# MCASP3_CFG register map
Vendor: Texas Instruments
Peripheral module from a debugger description file (folder J7_AHP).
Registers are 32-bit, read-write, reset 0x0 unless marked. A register's access mark holds for its fields unless they carry their own. Offsets are as the file gives them; lines under a group give offsets from that group; [hi:lo] are bit positions; {n}, {i} and the like mark numbered series; 'fields as' and 'values as' point back to an identical list; <NAME> marks a mode.

## MCASP3_CFG
0x00 CFG_PID ro reset 0x44307B02
  [31:0] REV — Identifies revision of peripheral.
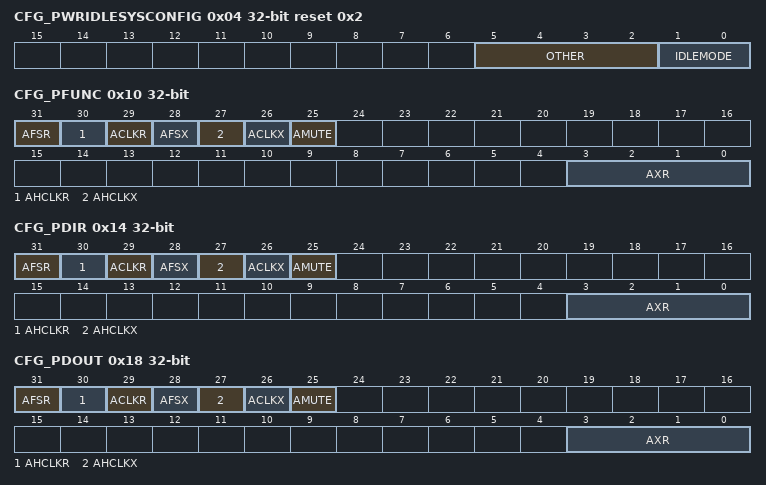
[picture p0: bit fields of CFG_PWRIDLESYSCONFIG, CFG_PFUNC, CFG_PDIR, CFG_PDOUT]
0x04 CFG_PWRIDLESYSCONFIG access per field reset 0x2
  [5:2] OTHER rw — Reserved for future programming.
  [1:0] IDLEMODE rw — Power management Configuration of the local target state management mode. By definition, target can handle read/write transaction as long as it is out of IDLE state.
0x10 CFG_PFUNC access per field
  [31] AFSR rw — Determines if AFSR pin functions as McASP or GPIO.
  [30] AHCLKR rw — Determines if AHCLKR pin functions as McASP or GPIO.
  [29] ACLKR rw — Determines if ACLKR pin functions as McASP or GPIO.
  [28] AFSX rw — Determines if AFSX pin functions as McASP or GPIO.
  [27] AHCLKX rw — Determines if AHCLKX pin functions as McASP or GPIO.
  [26] ACLKX rw — Determines if ACLKX pin functions as McASP or GPIO.
  [25] AMUTE rw — Determines if AMUTE pin functions as McASP or GPIO.
  [3:0] AXR rw — Determines if AXRn pin functions as McASP or GPIO.
0x14 CFG_PDIR access per field
  [31] AFSR rw — Determines if AFSR pin functions as an input or output.
  [30] AHCLKR rw — Determines if AHCLKR pin functions as an input or output.
  [29] ACLKR rw — Determines if ACLKR pin functions as an input or output.
  [28] AFSX rw — Determines if AFSX pin functions as an input or output.
  [27] AHCLKX rw — Determines if AHCLKX pin functions as an input or output.
  [26] ACLKX rw — Determines if ACLKX pin functions as an input or output.
  [25] AMUTE rw — Determines if AMUTE pin functions as an input or output.
  [3:0] AXR rw — Determines if AXRn pin functions as an input or output.
0x18 CFG_PDOUT access per field
  [31] AFSR rw — Determines drive on AFSR output pin when the corresponding PFUNC[31] and PDIR[31] bits are set to 1.
  [30] AHCLKR rw — Determines drive on AHCLKR output pin when the corresponding PFUNC[30] and PDIR[30] bits are set to 1.
  [29] ACLKR rw — Determines drive on ACLKR output pin when the corresponding PFUNC[29] and PDIR[29] bits are set to 1.
  [28] AFSX rw — Determines drive on AFSX output pin when the corresponding PFUNC[28] and PDIR[28] bits are set to 1.
  [27] AHCLKX rw — Determines drive on AHCLKX output pin when the corresponding PFUNC[27] and PDIR[27] bits are set to 1.
  [26] ACLKX rw — Determines drive on ACLKX output pin when the corresponding PFUNC[26] and PDIR[26] bits are set to 1.
  [25] AMUTE rw — Determines drive on AMUTE output pin when the corresponding PFUNC[25] and PDIR[25] bits are set to 1.
  [3:0] AXR rw — Determines drive on AXR[n] output pin when the corresponding PFUNC[n] and PDIR[n] bits are set to 1.
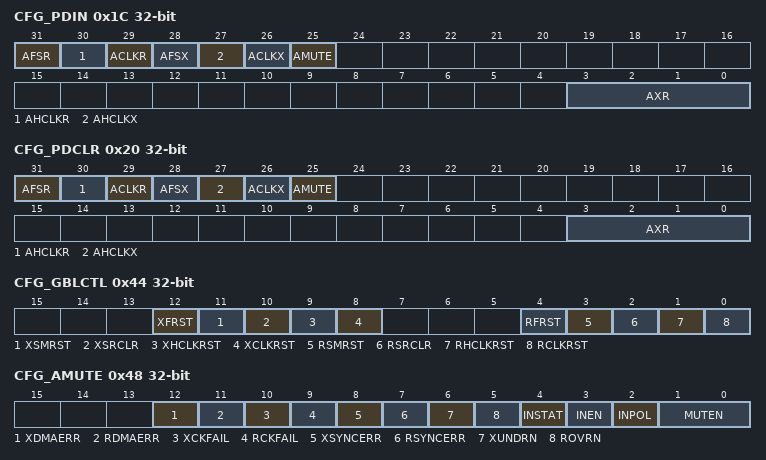
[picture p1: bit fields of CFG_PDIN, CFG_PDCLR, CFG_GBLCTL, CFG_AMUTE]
0x1C CFG_PDIN access per field
  [31] AFSR rw — Logic level on AFSR pin.
  [30] AHCLKR rw — Logic level on AHCLKR pin.
  [29] ACLKR rw — Logic level on ACLKR pin.
  [28] AFSX rw — Logic level on AFSX pin.
  [27] AHCLKX rw — Logic level on AHCLKX pin.
  [26] ACLKX rw — Logic level on ACLKX pin.
  [25] AMUTE rw — Logic level on AMUTE pin.
  [3:0] AXR rw — Logic level on AXR[n] pin.
0x20 CFG_PDCLR access per field
  [31] AFSR rw — Allows the corresponding AFSR bit in PDOUT to be cleared to a logic low without affecting other I/O pins controlled by the same port.
  [30] AHCLKR rw — Allows the corresponding AHCLKR bit in PDOUT to be cleared to a logic low without affecting other I/O pins controlled by the same port.
  [29] ACLKR rw — Allows the corresponding ACLKR bit in PDOUT to be cleared to a logic low without affecting other I/O pins controlled by the same port.
  [28] AFSX rw — Allows the corresponding AFSX bit in PDOUT to be cleared to a logic low without affecting other I/O pins controlled by the same port.
  [27] AHCLKX rw — Allows the corresponding AHCLKX bit in PDOUT to be cleared to a logic low without affecting other I/O pins controlled by the same port.
  [26] ACLKX rw — Allows the corresponding ACLKX bit in PDOUT to be cleared to a logic low without affecting other I/O pins controlled by the same port.
  [25] AMUTE rw — Allows the corresponding AMUTE bit in PDOUT to be cleared to a logic low without affecting other I/O pins controlled by the same port.
  [3:0] AXR rw — Allows the corresponding AXR[n] bit in PDOUT to be cleared to a logic low without affecting other I/O pins controlled by the same port.
0x44 CFG_GBLCTL access per field
  [12] XFRST rw — Transmit frame sync generator reset enable bit.
  [11] XSMRST rw — Transmit state machine reset enable bit.
  [10] XSRCLR rw — Transmit serializer clear enable bit. By clearing then setting this bit, the transmit buffer is flushed to an empty state [XDATA = 1]. If XSMRST = 1, XSRCLR = 1, XDATA = 1, and XBUF is not loaded with new data before the start of the next active time slot, an underrun will occur.
  [9] XHCLKRST rw — Transmit high-frequency clock divider reset enable bit.
  [8] XCLKRST rw — Transmit clock divider reset enable bit.
  [4] RFRST rw — Receive frame sync generator reset enable bit.
  [3] RSMRST rw — Receive state machine reset enable bit.
  [2] RSRCLR rw — Receive serializer clear enable bit. By clearing then setting this bit, the receive buffer is flushed.
  [1] RHCLKRST rw — Receive high-frequency clock divider reset enable bit.
  [0] RCLKRST rw — Receive high-frequency clock divider reset enable bit.
0x48 CFG_AMUTE access per field
  [12] XDMAERR rw — If transmit DMA error [XDMAERR], drive AMUTE active enable bit.
  [11] RDMAERR rw — If receive DMA error [RDMAERR], drive AMUTE active enable bit.
  [10] XCKFAIL rw — If transmit clock failure [XCKFAIL], drive AMUTE active enable bit.
  [9] RCKFAIL rw — If receive clock failure [RCKFAIL], drive AMUTE active enable bit.
  [8] XSYNCERR rw — If unexpected transmit frame sync error [XSYNCERR], drive AMUTE active enable bit.
  [7] RSYNCERR rw — If unexpected receive frame sync error [RSYNCERR], drive AMUTE active enable bit.
  [6] XUNDRN rw — If transmit underrun error [XUNDRN], drive AMUTE active enable bit.
  [5] ROVRN rw — If receiver overrun error [ROVRN], drive AMUTE active enable bit.
  [4] INSTAT ro — Determines drive on AXRn pin when PFUNC[n] and PDIR[n] bits are set to 1.
  [3] INEN rw — Drive AMUTE active when AMUTEIN error is active [INSTAT = 1].
  [2] INPOL rw — Audio mute in [AMUTEIN] polarity select bit.
  [1:0] MUTEN rw — AMUTE pin enable bit [unless overridden by GPIO registers].
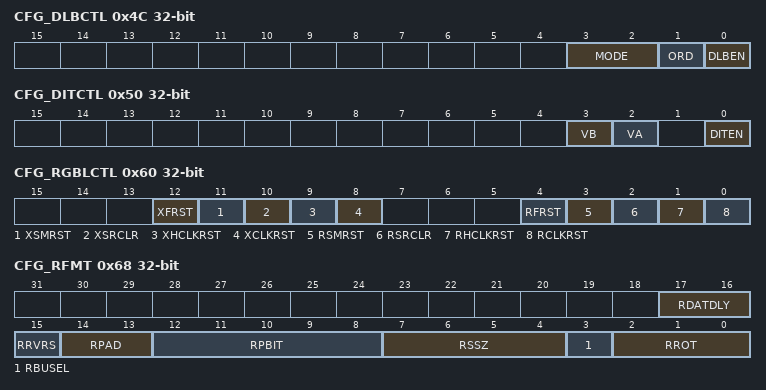
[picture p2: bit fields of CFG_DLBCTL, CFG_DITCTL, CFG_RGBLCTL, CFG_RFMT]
0x4C CFG_DLBCTL access per field
  [3:2] MODE rw — Loopback generator mode bits. Applies only when loopback mode is enabled [DLBEN = 1].
  [1] ORD rw — Loopback order bit when loopback mode is enabled [DLBEN = 1].
  [0] DLBEN rw — Loopback mode enable bit.
0x50 CFG_DITCTL access per field
  [3] VB rw — Valid bit for odd time slots [DIT right subframe].
  [2] VA rw — Valid bit for even time slots [DIT left subframe].
  [0] DITEN rw — DIT mode enable bit. DITEN should only be changed while the XSMRST bit in GBLCTL is in reset [and for startup, XSRCLR also in reset]. However, it is not necessary to reset the XCLKRST or XHCLKRST bits in GBLCTL to change DITEN.
0x60 CFG_RGBLCTL access per field
  [12] XFRST ro — Transmit frame sync generator reset enable bit. A read of this bit returns the XFRST bit value of GBLCTL. Writes have no effect.
  [11] XSMRST ro — Transmit state machine reset enable bit. A read of this bit returns the XSMRST bit value of GBLCTL. Writes have no effect.
  [10] XSRCLR ro — Transmit serializer clear enable bit. A read of this bit returns the XSRCLR bit value of GBLCTL. Writes have no effect.
  [9] XHCLKRST ro — Transmit high-frequency clock divider reset enable bit. A read of this bit returns the XHCLKRST bit value of GBLCTL. Writes have no effect.
  [8] XCLKRST ro — Transmit clock divider reset enable bit. A read of this bit returns the XCLKRST bit value of GBLCTL. Writes have no effect.
  [4] RFRST rw — Receive frame sync generator reset enable bit. A write to this bit affects the RFRST bit of GBLCTL.
  [3] RSMRST rw — Receive state machine reset enable bit. A write to this bit affects the RSMRST bit of GBLCTL.
  [2] RSRCLR rw — Receive serializer clear enable bit. A write to this bit affects the RSRCLR bit of GBLCTL.
  [1] RHCLKRST rw — Receive high-frequency clock divider reset enable bit. A write to this bit affects the RHCLKRST bit of GBLCTL.
  [0] RCLKRST rw — Receive clock divider reset enable bit. A write to this bit affects the RCLKRST bit of GBLCTL.
0x64 CFG_RMASK
  [31:0] RMASK — Receive data mask n enable bit.
0x68 CFG_RFMT access per field
  [17:16] RDATDLY rw — Receive bit delay.
  [15] RRVRS rw — Receive serial bitstream order.
  [14:13] RPAD rw — Pad value for extra bits in slot not belonging to the word. This field only applies to bits when RMASK[n] = 0.
  [12:8] RPBIT rw — RPBIT value determines which bit [as read by the CPU or DMA from RBUF[n]] is used to pad the extra bits. This field only applies when RPAD = 2h.
  [7:4] RSSZ rw — Receive slot size.
  [3] RBUSEL rw — Selects whether reads from serializer buffer XRBUF[n] originate from the configuration bus [CFG] or the data [DAT] port.
  [2:0] RROT rw — Right-rotation value for receive rotate right format unit.
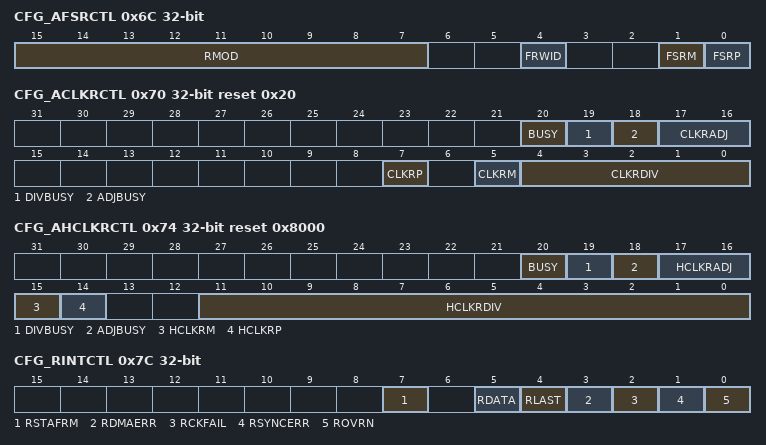
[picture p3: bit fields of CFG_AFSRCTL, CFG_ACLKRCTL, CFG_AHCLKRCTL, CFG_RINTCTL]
0x6C CFG_AFSRCTL access per field
  [15:7] RMOD rw — Receive frame sync mode select bits. 1FFh = Reserved from 181h to 1FFh.
  [4] FRWID rw — Receive frame sync width select bit indicates the width of the receive frame sync [AFSR] during its active period.
  [1] FSRM rw — Receive frame sync generation select bit.
  [0] FSRP rw — Receive frame sync polarity select bit.
0x70 CFG_ACLKRCTL access per field reset 0x20
  [20] BUSY rw — Status: logical OR of DIVBUSY, ADJBUSY
  [19] DIVBUSY rw — Status: divide ratio change in progress
  [18] ADJBUSY rw — Status: one-shot adjustment in progress
  [17:16] CLKRADJ wo — CLKRDIV one-shot adjustment
  [7] CLKRP rw — Receive bitstream clock polarity select bit.
  [5] CLKRM rw — Receive bit clock source bit. Note that this bit does not have any effect, if ACLKXCTL.ASYNC = 0.
  [4:0] CLKRDIV rw — Receive bit clock divide ratio bits determine the divide-down ratio from AHCLKR to ACLKR. Note that this bit does not have any effect, if ACLKXCTL.ASYNC = 0.
0x74 CFG_AHCLKRCTL access per field reset 0x8000
  [20] BUSY rw — Status: logical OR of DIVBUSY, ADJBUSY
  [19] DIVBUSY rw — Status: divide ratio change in progress?
  [18] ADJBUSY rw — Status: one-shot adjustment in progress?
  [17:16] HCLKRADJ wo — HCLKRDIV one-shot adjustment
  [15] HCLKRM rw — Receive high-frequency clock source bit.
  [14] HCLKRP rw — Receive bitstream high-frequency clock polarity select bit.
  [11:0] HCLKRDIV rw — Receive high-frequency clock divide ratio bits determine the divide-down ratio from AUXCLK to AHCLKR.
0x78 CFG_RTDM
  [31:0] RTDMS — Receiver mode during TDM time slot n.
0x7C CFG_RINTCTL access per field
  [7] RSTAFRM rw — Receive start of frame interrupt enable bit.
  [5] RDATA rw — Receive data ready interrupt enable bit.
  [4] RLAST rw — Receive last slot interrupt enable bit.
  [3] RDMAERR rw — Receive DMA error interrupt enable bit.
  [2] RCKFAIL rw — Receive clock failure interrupt enable bit.
  [1] RSYNCERR rw — Unexpected receive frame sync interrupt enable bit.
  [0] ROVRN rw — Receiver overrun interrupt enable bit.
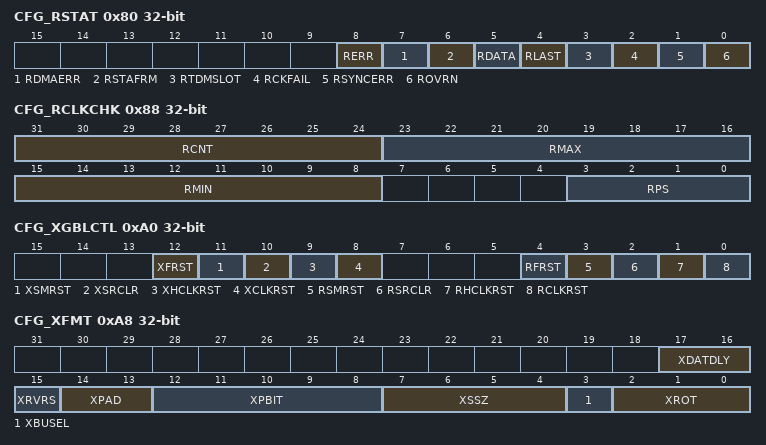
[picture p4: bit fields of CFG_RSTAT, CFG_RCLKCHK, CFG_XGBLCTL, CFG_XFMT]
0x80 CFG_RSTAT access not given
  [8] RERR rw — RERR bit always returns a logic-OR of: ROVRN OR RSYNCERR OR RCKFAIL OR RDMAERR. Allows a single bit to be checked to determine if a receiver error interrupt has occurred.
  [7] RDMAERR — Receive DMA error flag. RDMAERR is set when the CPU or DMA reads more serializers through the data port in a given time slot than were programmed as receivers. Causes a receive interrupt [RINT], if this bit is set and RDMAERR in RINTCTL is set. This bit is cleared by writing a 1 to this bit. Writing a 0 to this bit has no effect. (access R/W1TC)
  [6] RSTAFRM — Receive start of frame flag. Causes a receive interrupt [RINT], if this bit is set and RSTAFRM in RINTCTL is set. This bit is cleared by writing a 1 to this bit. Writing a 0 to this bit has no effect. (access R/W1TC)
  [5] RDATA — Receive data ready flag. Causes a receive interrupt [RINT], if this bit is set and RDATA in RINTCTL is set. This bit is cleared by writing a 1 to this bit. Writing a 0 to this bit has no effect. (access R/W1TC)
  [4] RLAST — Receive last slot flag. RLAST is set along with RDATA, if the current slot is the last slot in a frame. Causes a receive interrupt [RINT], if this bit is set and RLAST in RINTCTL is set. This bit is cleared by writing a 1 to this bit. Writing a 0 to this bit has no effect. (access R/W1TC)
  [3] RTDMSLOT ro — Returns the LSB of RSLOT. Allows a single read of RSTAT to determine whether the current TDM time slot is even or odd.
  [2] RCKFAIL — Receive clock failure flag. RCKFAIL is set when the receive clock failure detection circuit reports an error. Causes a receive interrupt [RINT], if this bit is set and RCKFAIL in RINTCTL is set. This bit is cleared by writing a 1 to this bit. Writing a 0 to this bit has no effect. (access R/W1TC)
  [1] RSYNCERR — Unexpected receive frame sync flag. RSYNCERR is set when a new receive frame sync [AFSR] occurs before it is expected. Causes a receive interrupt [RINT], if this bit is set and RSYNCERR in RINTCTL is set. This bit is cleared by writing a 1 to this bit. Writing a 0 to this bit has no effect. (access R/W1TC)
  [0] ROVRN — Receiver overrun flag. ROVRN is set when the receive serializer is instructed to transfer data from XRSR to RBUF, but the former data in RBUF has not yet been read by the CPU or DMA. Causes a receive interrupt [RINT], if this bit is set and ROVRN in RINTCTL is set. This bit is cleared by writing a 1 to this bit. Writing a 0 to this bit has no effect. (access R/W1TC)
0x84 CFG_RSLOT ro
  [8:0] RSLOTCNT — 0-17Fh = Current receive time slot count. Legal values: 0 to 383 [17Fh]. TDM function is not supported for > 32 time slots. However, TDM time slot counter may count to 383 when used to receive a DIR block [transferred over TDM format].
0x88 CFG_RCLKCHK access per field
  [31:24] RCNT ro — Receive clock count value [from previous measurement]. The clock circuit continually counts the number of system clocks for every 32 receive high-frequency master clock [AHCLKR] signals, and stores the count in RCNT until the next measurement is taken.
  [23:16] RMAX rw — Receive clock maximum boundary. This 8 bit unsigned value sets the maximum allowed boundary for the clock check counter after 32 receive high-frequency master clock [AHCLKR] signals have been received. If the current counter value is greater than RMAX after counting 32 AHCLKR signals, RCKFAIL in RSTAT is set. The comparison is performed using unsigned arithmetic.
  [15:8] RMIN rw — Receive clock minimum boundary. This 8 bit unsigned value sets the minimum allowed boundary for the clock check counter after 32 receive high-frequency master clock [AHCLKR] signals have been received. If RCNT is less than RMIN after counting 32 AHCLKR signals, RCKFAIL in RSTAT is set. The comparison is performed using unsigned arithmetic.
  [3:0] RPS rw — Receive clock check prescaler value.
0x8C CFG_PIDTCTL access per field
  [0] RDATDMA rw — Receive data DMA request enable bit. If writing to this bit, always write the default value of 0.
0xA0 CFG_XGBLCTL access per field
  [12] XFRST rw — Transmit frame sync generator reset enable bit. A write to this bit affects the XFRST bit of GBLCTL.
  [11] XSMRST rw — Transmit state machine reset enable bit. A write to this bit affects the XSMRST bit of GBLCTL.
  [10] XSRCLR rw — Transmit serializer clear enable bit. A write to this bit affects the XSRCLR bit of GBLCTL.
  [9] XHCLKRST rw — Transmit high-frequency clock divider reset enable bit. A write to this bit affects the XHCLKRST bit of GBLCTL.
  [8] XCLKRST rw — Transmit clock divider reset enable bit. A write to this bit affects the XCLKRST bit of GBLCTL.
  [4] RFRST ro — Receive frame sync generator reset enable bit. A read of this bit returns the RFRST bit value of GBLCTL. Writes have no effect.
  [3] RSMRST ro — Receive state machine reset enable bit. A read of this bit returns the RSMRST bit value of GBLCTL. Writes have no effect.
  [2] RSRCLR ro — Receive serializer clear enable bit. A read of this bit returns the RSRSCLR bit value of GBLCTL. Writes have no effect.
  [1] RHCLKRST ro — Receive high-frequency clock divider reset enable bit. A read of this bit returns the RHCLKRST bit value of GBLCTL. Writes have no effect.
  [0] RCLKRST ro — Receive clock divider reset enable bit. A read of this bit returns the RCLKRST bit value of GBLCTL. Writes have no effect.
0xA4 CFG_XMASK
  [31:0] XMASK — Transmit data mask n enable bit.
0xA8 CFG_XFMT access per field
  [17:16] XDATDLY rw — Transmit sync bit delay.
  [15] XRVRS rw — Transmit serial bitstream order.
  [14:13] XPAD rw — Pad value for extra bits in slot not belonging to word defined by XMASK. This field only applies to bits when XMASK[n] = 0.
  [12:8] XPBIT rw — XPBIT value determines which bit [as written by the CPU or DMA to XBUF[n]] is used to pad the extra bits before shifting. This field only applies when XPAD = 2h.
  [7:4] XSSZ rw — Transmit slot size.
  [3] XBUSEL rw — Selects whether writes to serializer buffer XRBUF[n] originate from the configuration bus [CFG] or the data [DAT] port.
  [2:0] XROT rw — Right-rotation value for transmit rotate right format unit.
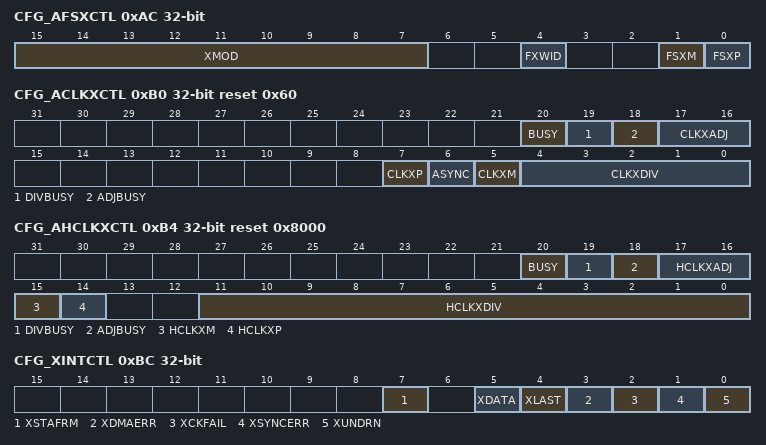
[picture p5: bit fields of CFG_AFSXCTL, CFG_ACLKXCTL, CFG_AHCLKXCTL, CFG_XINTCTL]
0xAC CFG_AFSXCTL access per field
  [15:7] XMOD rw — Transmit frame sync mode select bits. 1FFh = Reserved from 181h to 1FFh.
  [4] FXWID rw — Transmit frame sync width select bit indicates the width of the transmit frame sync [AFSX] during its active period.
  [1] FSXM rw — Transmit frame sync generation select bit.
  [0] FSXP rw — Transmit frame sync polarity select bit.
0xB0 CFG_ACLKXCTL access per field reset 0x60
  [20] BUSY rw — Status: logical OR of DIVBUSY, ADJBUSY
  [19] DIVBUSY rw — Status: divide ratio change in progress
  [18] ADJBUSY rw — Status: one-shot adjustment in progress
  [17:16] CLKXADJ wo — CLKXDIV one-shot adjustment
  [7] CLKXP rw — Transmit bitstream clock polarity select bit.
  [6] ASYNC rw — Transmit/receive operation asynchronous enable bit.
  [5] CLKXM rw — Transmit bit clock source bit.
  [4:0] CLKXDIV rw — Transmit bit clock divide ratio bits determine the divide-down ratio from AHCLKX to ACLKX.
0xB4 CFG_AHCLKXCTL access per field reset 0x8000
  [20] BUSY rw — Status: logical OR of DIVBUSY, ADJBUSY
  [19] DIVBUSY rw — Status: divide ratio change in progress?
  [18] ADJBUSY rw — Status: one-shot adjustment in progress?
  [17:16] HCLKXADJ wo — HCLKXDIV one-shot adjustment
  [15] HCLKXM rw — Transmit high-frequency clock source bit.
  [14] HCLKXP rw — Transmit bitstream high-frequency clock polarity select bit.
  [11:0] HCLKXDIV rw — Transmit high-frequency clock divide ratio bits determine the divide-down ratio from AUXCLK to AHCLKX.
0xB8 CFG_XTDM
  [31:0] XTDMS — Transmitter mode during TDM time slot n.
0xBC CFG_XINTCTL access per field
  [7] XSTAFRM rw — Transmit start of frame interrupt enable bit.
  [5] XDATA rw — Transmit data ready interrupt enable bit.
  [4] XLAST rw — Transmit last slot interrupt enable bit.
  [3] XDMAERR rw — Transmit DMA error interrupt enable bit.
  [2] XCKFAIL rw — Transmit clock failure interrupt enable bit.
  [1] XSYNCERR rw — Unexpected transmit frame sync interrupt enable bit.
  [0] XUNDRN rw — Transmitter underrun interrupt enable bit.
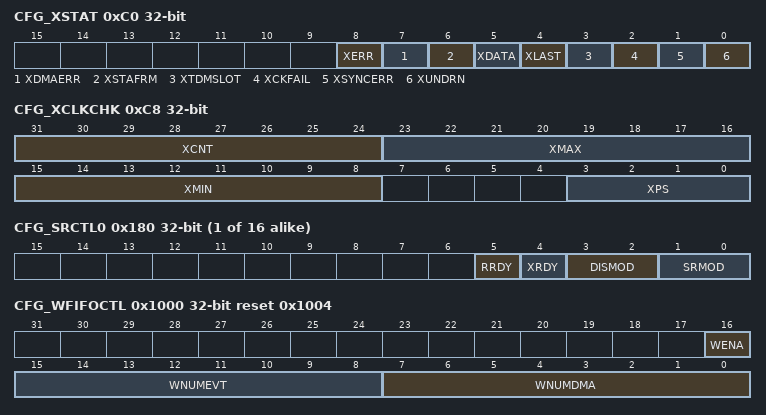
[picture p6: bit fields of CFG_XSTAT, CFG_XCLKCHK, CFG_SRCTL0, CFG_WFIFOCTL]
0xC0 CFG_XSTAT access not given
  [8] XERR rw — XERR bit always returns a logic-OR of: XUNDRN OR XSYNCERR OR XCKFAIL OR XDMAERR. Allows a single bit to be checked to determine if a transmitter error interrupt has occurred.
  [7] XDMAERR — Transmit DMA error flag. XDMAERR is set when the CPU or DMA writes more serializers through the data port in a given time slot than were programmed as transmitters. Causes a transmit interrupt [XINT], if this bit is set and XDMAERR in XINTCTL is set. This bit is cleared by writing a 1 to this bit. Writing a 0 has no effect. (access R/W1TC)
  [6] XSTAFRM — Transmit start of frame flag. Causes a transmit interrupt [XINT], if this bit is set and XSTAFRM in XINTCTL is set. This bit is cleared by writing a 1 to this bit. Writing a 0 has no effect. (access R/W1TC)
  [5] XDATA — Transmit data ready flag. Causes a transmit interrupt [XINT], if this bit is set and XDATA in XINTCTL is set. This bit is cleared by writing a 1 to this bit. Writing a 0 has no effect. (access R/W1TC)
  [4] XLAST — Transmit last slot flag. XLAST is set along with XDATA, if the current slot is the last slot in a frame. Causes a transmit interrupt [XINT], if this bit is set and XLAST in XINTCTL is set. This bit is cleared by writing a 1 to this bit. Writing a 0 has no effect. (access R/W1TC)
  [3] XTDMSLOT ro — Returns the LSB of XSLOT. Allows a single read of XSTAT to determine whether the current TDM time slot is even or odd.
  [2] XCKFAIL — Transmit clock failure flag. XCKFAIL is set when the transmit clock failure detection circuit reports an error. Causes a transmit interrupt [XINT], if this bit is set and XCKFAIL in XINTCTL is set. This bit is cleared by writing a 1 to this bit. Writing a 0 has no effect. (access R/W1TC)
  [1] XSYNCERR — Unexpected transmit frame sync flag. XSYNCERR is set when a new transmit frame sync [AFSX] occurs before it is expected. Causes a transmit interrupt [XINT], if this bit is set and XSYNCERR in XINTCTL is set. This bit is cleared by writing a 1 to this bit. Writing a 0 has no effect. (access R/W1TC)
  [0] XUNDRN — Transmitter underrun flag. XUNDRN is set when the transmit serializer is instructed to transfer data from XBUF to XRSR, but XBUF has not yet been serviced with new data since the last transfer. Causes a transmit interrupt [XINT], if this bit is set and XUNDRN in XINTCTL is set. This bit is cleared by writing a 1 to this bit. Writing a 0 has no effect. (access R/W1TC)
0xC4 CFG_XSLOT ro reset 0x17F
  [9:0] XSLOTCNT — Current transmit time slot count. Legal values: 0 to 383 [17Fh]. During reset, this counter value is 383 so the next count value, which is used to encode the first DIT group of data, will be 0 and encodes the B preamble. TDM function is not supported for >32 time slots. However, TDM time slot counter may count to 383 when used to transmit a DIT block.
0xC8 CFG_XCLKCHK access per field
  [31:24] XCNT ro — Transmit clock count value [from previous measurement]. The clock circuit continually counts the number of system clocks for every 32 transmit high-frequency master clock [AHCLKX] signals, and stores the count in XCNT until the next measurement is taken.
  [23:16] XMAX rw — Transmit clock maximum boundary. This 8 bit unsigned value sets the maximum allowed boundary for the clock check counter after 32 transmit high-frequency master clock [AHCLKX] signals have been received. If the current counter value is greater than XMAX after counting 32 AHCLKX signals, XCKFAIL in XSTAT is set. The comparison is performed using unsigned arithmetic.
  [15:8] XMIN rw — Transmit clock minimum boundary. This 8 bit unsigned value sets the minimum allowed boundary for the clock check counter after 32 transmit high-frequency master clock [AHCLKX] signals have been received. If XCNT is less than XMIN after counting 32 AHCLKX signals, XCKFAIL in XSTAT is set. The comparison is performed using unsigned arithmetic.
  [3:0] XPS rw — Transmit clock check prescaler value. Fh = Reserved from 9h to Fh.
0xCC CFG_XEVTCTL access per field
  [0] XDATDMA rw — Transmit data DMA request enable bit. If writing to this bit, always write the default value of 0.
{0x100+4i} CFG_DITCSRA{i} (i=0..5)
  [31:0] DITCSRA — DIT left channel status registers.
{0x118+4i} CFG_DITCSRB{i} (i=0..5)
  [31:0] DITCSRB — DIT right channel status registers.
{0x130+4i} CFG_DITUDRA{i} (i=0..5)
  [31:0] DITUDRA — DIT left channel user data registers.
{0x148+4i} CFG_DITUDRB{i} (i=0..5)
  [31:0] DITUDRB — DIT right channel user data registers.
{0x180+4i} CFG_SRCTL{i} access per field (i=0..15)
  [5] RRDY ro — Receive buffer ready bit. RRDY indicates the current receive buffer state. Always reads 0 when programmed as a transmitter or as inactive. If SRMOD bit is set to receive [2h], RRDY switches from 0 to 1 whenever data is transferred from XRSR to RBUF.
  [4] XRDY ro — Transmit buffer ready bit. XRDY indicates the current transmit buffer state. Always reads 0 when programmed as a receiver or as inactive. If SRMOD bit is set to transmit [1h], XRDY switches from 0 to 1 when XSRCLR in GBLCTL is switched from 0 to 1 to indicate an empty transmitter. XRDY remains set until XSRCLR is forced to 0, data is written to the corresponding transmit buffer, or SRMOD bit is changed to receive [2h] or inactive [0].
  [3:2] DISMOD rw — Serializer pin drive mode bit. Drive on pin when in inactive TDM slot of transmit mode or when serializer is inactive. This field only applies if the pin is configured as a McASP pin [PFUNC = 0].
  [1:0] SRMOD rw — Serializer mode bit.
{0x200+4i} CFG_XBUF{i} (i=0..15)
  [31:0] XBUF — Transmit buffers for serializers.
{0x280+4i} CFG_RBUF{i} (i=0..15)
  [31:0] RBUF — Receive buffers for serializers.
0x1000 CFG_WFIFOCTL access per field reset 0x1004
  [16] WENA rw — Write FIFO enable bit.
  [15:8] WNUMEVT rw — Write word count per DMA event [32 bit]. When the Write FIFO has space for at least WNUMEVT words of data, then an AXEVT [transmit DMA event] is generated to the host/DMA controller. This value should be set to a non-zero integer multiple of the number of serializers enabled as transmitters. This value must be set prior to enabling the Write FIFO. 416h = 3 to 64 words from 3h to 416h. FFh = Reserved from 41h to FFh.
  [7:0] WNUMDMA rw — Write word count per transfer [32 bit words]. Upon a transmit DMA event from the McASP, WNUMDMA words are transferred from the Write FIFO to the McASP. This value must equal the number of McASP serializers used as transmitters. This value must be set prior to enabling the Write FIFO. FFh = Reserved from 11h to FFh.
0x1004 CFG_WFIFOSTS ro
  [7:0] WLVL — Write level [read-only]. Number of 32 bit words currently in the Write FIFO. 40h = 3 to 64 words currently in Write FIFO from 3h to 40h. FFh = Reserved from 41h to FFh.
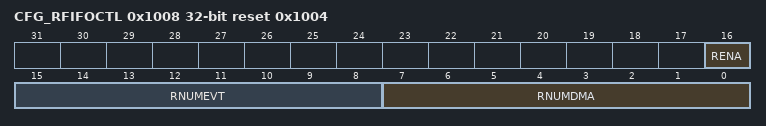
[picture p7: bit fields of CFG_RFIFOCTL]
0x1008 CFG_RFIFOCTL access per field reset 0x1004
  [16] RENA rw — Read FIFO enable bit.
  [15:8] RNUMEVT rw — Read word count per DMA event [32 bit]. When the Read FIFO contains at least RNUMEVT words of data, then an AREVT [receive DMA event] is generated to the host/DMA controller. This value should be set to a non-zero integer multiple of the number of serializers enabled as receivers. This value must be set prior to enabling the Read FIFO. 416h = 3 to 64 words from 3h to 416h. FFh = Reserved from 41h = FFh.
  [7:0] RNUMDMA rw — Read word count per transfer [32 bit words]. Upon a receive DMA event from the McASP, the Read FIFO reads RNUMDMA words from the McASP. This value must equal the number of McASP serializers used as receivers. This value must be set prior to enabling the Read FIFO. 10h = 3 to 16 words from 3h to 10h. FFh = Reserved from 11h to FFh.
0x100C CFG_RFIFOSTS ro
  [7:0] RLVL — Read level [read-only]. Number of 32 bit words currently in the Read FIFO. 40h = 3 to 64 words currently in Read FIFO from 3h to 40h. FFh = Reserved from 41h to FFh.
